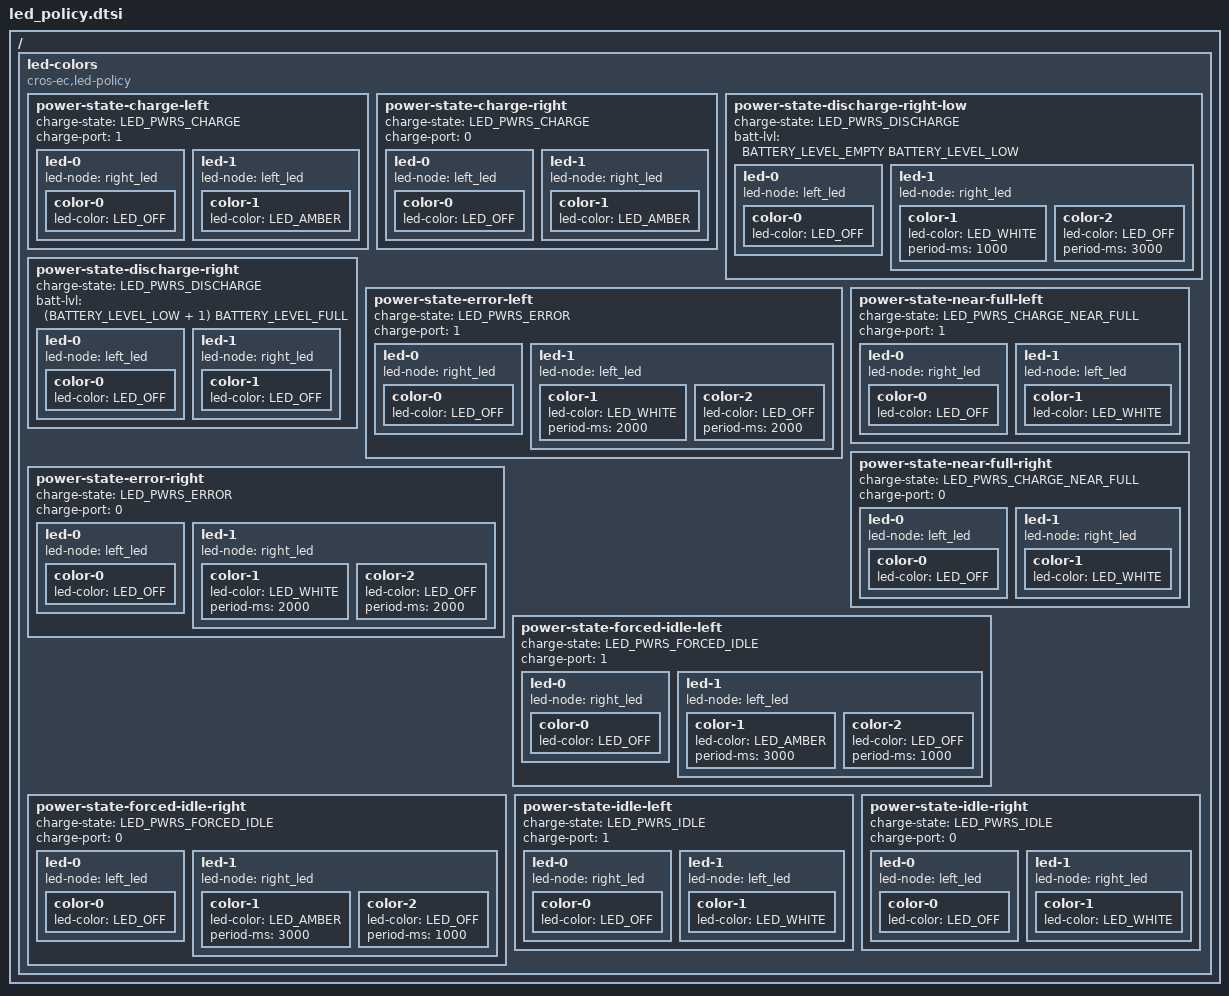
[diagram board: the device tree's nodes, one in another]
#include <dt-bindings/battery.h>

/ {
	led-colors {
		compatible = "cros-ec,led-policy";

		power-state-charge-left {
			charge-state = "LED_PWRS_CHARGE";
			charge-port = <1>; /* Left port */

			led-0 {
				led-node = <&right_led>;

				/* Turn off the right LED */
				color-0 {
					led-color = "LED_OFF";
				};
			};

			led-1 {
				led-node = <&left_led>;
				/* Left LED to Amber */
				color-1 {
					led-color = "LED_AMBER";
				};
			};
		};

		power-state-charge-right {
			charge-state = "LED_PWRS_CHARGE";
			charge-port = <0>; /* Right port */

			led-0 {
				led-node = <&left_led>;

				/* Turn off the left LED */
				color-0 {
					led-color = "LED_OFF";
				};
			};

			led-1 {
				led-node = <&right_led>;
				/* Right LED to Amber */
				color-1 {
					led-color = "LED_AMBER";
				};
			};
		};

		power-state-discharge-right-low {
			charge-state = "LED_PWRS_DISCHARGE";
			/* Battery percent range (>= Empty, <= Low) */
			batt-lvl = <BATTERY_LEVEL_EMPTY BATTERY_LEVEL_LOW>;

			led-0 {
				led-node = <&left_led>;

				/* Turn off the left LED */
				color-0 {
					led-color = "LED_OFF";
				};
			};

			led-1 {
				led-node = <&right_led>;
				/* Right LED - White 1 sec, off 3 sec */
				color-1 {
					led-color = "LED_WHITE";
					period-ms = <1000>;
				};
				color-2 {
					led-color = "LED_OFF";
					period-ms = <3000>;
				};
			};
		};

		power-state-discharge-right {
			charge-state = "LED_PWRS_DISCHARGE";
			/* Battery percent range (> Low, <= Full) */
			batt-lvl = <(BATTERY_LEVEL_LOW + 1) BATTERY_LEVEL_FULL>;

			led-0 {
				led-node = <&left_led>;

				/* Turn off the left LED */
				color-0 {
					led-color = "LED_OFF";
				};
			};

			led-1 {
				led-node = <&right_led>;
				/* Turn off the right LED */
				color-1 {
					led-color = "LED_OFF";
				};
			};
		};

		power-state-error-left {
			charge-state = "LED_PWRS_ERROR";
			charge-port = <1>; /* Left port */

			led-0 {
				led-node = <&right_led>;

				/* Turn off the right LED */
				color-0 {
					led-color = "LED_OFF";
				};
			};

			led-1 {
				led-node = <&left_led>;
				/* Left LED - White 2 sec, off 2 sec */
				color-1 {
					led-color = "LED_WHITE";
					period-ms = <2000>;
				};
				color-2 {
					led-color = "LED_OFF";
					period-ms = <2000>;
				};
			};
		};

		power-state-error-right {
			charge-state = "LED_PWRS_ERROR";
			charge-port = <0>; /* Right port */

			led-0 {
				led-node = <&left_led>;

				/* Turn off the left LED */
				color-0 {
					led-color = "LED_OFF";
				};
			};

			led-1 {
				led-node = <&right_led>;
				/* Right LED - White 2 sec, off 2 sec */
				color-1 {
					led-color = "LED_WHITE";
					period-ms = <2000>;
				};
				color-2 {
					led-color = "LED_OFF";
					period-ms = <2000>;
				};
			};
		};

		power-state-near-full-left {
			charge-state = "LED_PWRS_CHARGE_NEAR_FULL";
			charge-port = <1>; /* Left port */

			led-0 {
				led-node = <&right_led>;

				/* Turn off the right LED */
				color-0 {
					led-color = "LED_OFF";
				};
			};

			led-1 {
				led-node = <&left_led>;
				/* Left LED to White */
				color-1 {
					led-color = "LED_WHITE";
				};
			};
		};

		power-state-near-full-right {
			charge-state = "LED_PWRS_CHARGE_NEAR_FULL";
			charge-port = <0>; /* Right port */

			led-0 {
				led-node = <&left_led>;

				/* Turn off the left LED */
				color-0 {
					led-color = "LED_OFF";
				};
			};

			led-1 {
				led-node = <&right_led>;
				/* Right LED to White */
				color-1 {
					led-color = "LED_WHITE";
				};
			};
		};

		power-state-forced-idle-left {
			charge-state = "LED_PWRS_FORCED_IDLE";
			charge-port = <1>; /* Left port */

			led-0 {
				led-node = <&right_led>;

				/* Turn off the right LED */
				color-0 {
					led-color = "LED_OFF";
				};
			};

			led-1 {
				led-node = <&left_led>;
				/* Left LED - Amber 3 sec, Off 1 sec */
				color-1 {
					led-color = "LED_AMBER";
					period-ms = <3000>;
				};
				color-2 {
					led-color = "LED_OFF";
					period-ms = <1000>;
				};
			};
		};

		power-state-forced-idle-right {
			charge-state = "LED_PWRS_FORCED_IDLE";
			charge-port = <0>; /* Right port */

			led-0 {
				led-node = <&left_led>;

				/* Turn off the left LED */
				color-0 {
					led-color = "LED_OFF";
				};
			};

			led-1 {
				led-node = <&right_led>;
				/* Right LED - Amber 3 sec, Off 1 sec */
				color-1 {
					led-color = "LED_AMBER";
					period-ms = <3000>;
				};
				color-2 {
					led-color = "LED_OFF";
					period-ms = <1000>;
				};
			};
		};

		power-state-idle-left {
			charge-state = "LED_PWRS_IDLE";
			charge-port = <1>; /* Left port */

			led-0 {
				led-node = <&right_led>;

				/* Turn off the right LED */
				color-0 {
					led-color = "LED_OFF";
				};
			};

			led-1 {
				led-node = <&left_led>;
				/* Left LED to White */
				color-1 {
					led-color = "LED_WHITE";
				};
			};
		};

		power-state-idle-right {
			charge-state = "LED_PWRS_IDLE";
			charge-port = <0>; /* Right port */

			led-0 {
				led-node = <&left_led>;

				/* Turn off the left LED */
				color-0 {
					led-color = "LED_OFF";
				};
			};

			led-1 {
				led-node = <&right_led>;
				/* Right LED to White */
				color-1 {
					led-color = "LED_WHITE";
				};
			};
		};
	};
};
